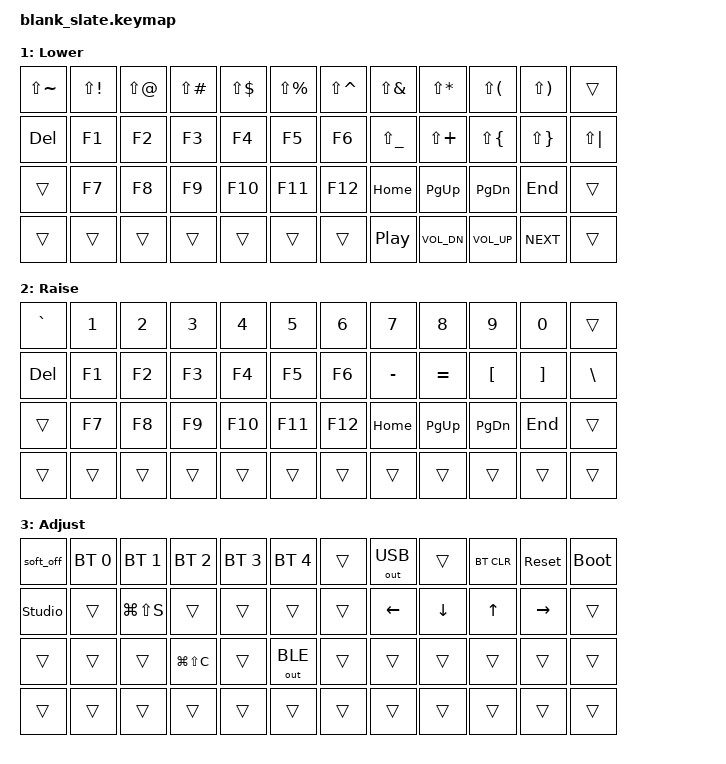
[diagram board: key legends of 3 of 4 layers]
/*
 * Copyright (c) 2022 Pete Johanson
 *
 * SPDX-License-Identifier: MIT
 */

#include <behaviors.dtsi>
#include <dt-bindings/zmk/keys.h>
#include <dt-bindings/zmk/bt.h>
#include <dt-bindings/zmk/outputs.h>

// Using layer taps on thumbs, having quick tap as well helps w/ repeating space/backspace
&lt { quick_tap_ms = <200>; };

/ {
    chosen {
       zmk,physical-layout =
                       &layout_ortho_4x12_1x2u;
    };

    keymap {
        compatible = "zmk,keymap";

        base {
            display-name = "Base";
            bindings = <
&kp ESC    &kp Q            &kp W     &kp E     &kp R  &kp T      &kp Y  &kp U     &kp I      &kp O     &kp P      &kp BSPC
&kp TAB    &kp A            &kp S     &kp D     &kp F  &kp G      &kp H  &kp J     &kp K      &kp L     &kp SEMI   &kp SQT
&kp LSHFT  &kp Z            &kp X     &kp C     &kp V  &kp B      &kp N  &kp M     &kp COMMA  &kp DOT   &kp SLASH  &kp RET
&kp LCTRL  &kp LC(LA(DEL))  &kp LGUI  &kp LALT  &mo 1  &kp SPACE  &mo 2  &kp LEFT  &kp DOWN   &kp UP    &kp RIGHT
            >;
        };

        lower {
            display-name = "Lower";
            bindings = <
&kp LS(TILDE)  &kp LS(EXCL)  &kp LS(AT)  &kp LS(POUND)  &kp LS(DLLR)  &kp LS(PRCNT)  &kp LS(CARET)  &kp LS(AMPS)   &kp LS(STAR)  &kp LS(LPAR)  &kp LS(RPAR)  &trans
&kp DEL        &kp F1        &kp F2      &kp F3         &kp F4        &kp F5         &kp F6         &kp LS(UNDER)  &kp LS(PLUS)  &kp LS(LBRC)  &kp LS(RBRC)  &kp LS(PIPE)
&trans         &kp F7        &kp F8      &kp F9         &kp F10       &kp F11        &kp F12        &kp HOME       &kp PG_UP     &kp PG_DN     &kp END       &trans
&trans         &trans        &trans      &trans         &trans        &trans         &trans         &kp C_PP       &kp C_VOL_DN  &kp C_VOL_UP  &kp C_NEXT    &trans
            >;
        };

        raise {
            display-name = "Raise";
            bindings = <
&kp GRAVE  &kp N1  &kp N2  &kp N3  &kp N4   &kp N5   &kp N6   &kp N7     &kp N8     &kp N9     &kp N0    &trans
&kp DEL    &kp F1  &kp F2  &kp F3  &kp F4   &kp F5   &kp F6   &kp MINUS  &kp EQUAL  &kp LBKT   &kp RBKT  &kp BSLH
&trans     &kp F7  &kp F8  &kp F9  &kp F10  &kp F11  &kp F12  &kp HOME   &kp PG_UP  &kp PG_DN  &kp END   &trans
&trans     &trans  &trans  &trans  &trans   &trans   &trans   &trans     &trans     &trans     &trans    &trans
            >;
        };

        adjust {
            display-name = "Adjust";
            bindings = <
&soft_off  &bt BT_SEL 0  &bt BT_SEL 1   &bt BT_SEL 2   &bt BT_SEL 3  &bt BT_SEL 4  &trans  &out OUT_USB  &trans    &bt BT_CLR  &sys_reset  &bootloader
&studio_unlock     &trans        &kp LG(LS(S))  &trans         &trans        &trans        &trans  &kp LEFT      &kp DOWN  &kp UP      &kp RIGHT   &trans
&trans     &trans        &trans         &kp LG(LS(C))  &trans        &out OUT_BLE  &trans  &trans        &trans    &trans      &trans      &trans
&trans     &trans        &trans         &trans         &trans        &trans        &trans  &trans        &trans    &trans      &trans      &trans
            >;
        };

        extra1 {
            status = "reserved";
        };

        extra2 {
            status = "reserved";
        };

        extra3 {
            status = "reserved";
        };

        extra4 {
            status = "reserved";
        };

    };

    conditional_layers {
        compatible = "zmk,conditional-layers";

        adjust {
            if-layers = <1 2>;
            then-layer = <3>;
        };
    };
};

